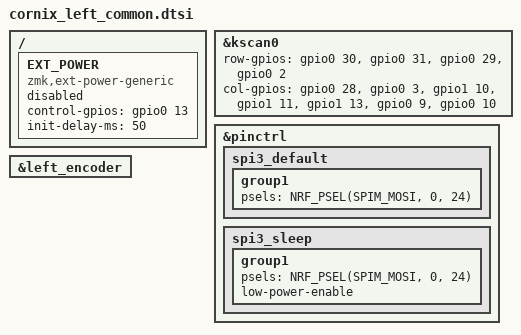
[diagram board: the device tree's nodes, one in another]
#include "cornix.dtsi"

/ {
    EXT_POWER {
        status = "disabled";
        compatible = "zmk,ext-power-generic";
        control-gpios = <&gpio0 13 GPIO_ACTIVE_HIGH>;
        init-delay-ms = <50>;
    };
};

&kscan0 {
    row-gpios
    = <&gpio0 30 (GPIO_ACTIVE_HIGH | GPIO_PULL_DOWN)>  // Row 0
    , <&gpio0 31 (GPIO_ACTIVE_HIGH | GPIO_PULL_DOWN)>  // Row 1
    , <&gpio0 29 (GPIO_ACTIVE_HIGH | GPIO_PULL_DOWN)>  // Row 2
    , <&gpio0 2  (GPIO_ACTIVE_HIGH | GPIO_PULL_DOWN)>  // Row 3
    ;

    col-gpios
    = <&gpio0 28 GPIO_ACTIVE_HIGH>  // Col 0
    , <&gpio0  3 GPIO_ACTIVE_HIGH>  // Col 1
    , <&gpio1 10 GPIO_ACTIVE_HIGH>  // Col 2
    , <&gpio1 11 GPIO_ACTIVE_HIGH>  // Col 3
    , <&gpio1 13 GPIO_ACTIVE_HIGH>  // Col 4
    , <&gpio0  9 GPIO_ACTIVE_HIGH>  // Col 5
    , <&gpio0 10 GPIO_ACTIVE_HIGH>  // Col 6
    ;
};

// rgb,SPI
&pinctrl {
    spi3_default: spi3_default {
        group1 {
            psels = <NRF_PSEL(SPIM_MOSI, 0, 24)>;
        };
    };

    spi3_sleep: spi3_sleep {
        group1 {
            psels = <NRF_PSEL(SPIM_MOSI, 0, 24)>;
            low-power-enable;
        };
    };
};

&left_encoder {
    status = "okay";
};
